AUTOSAR XML (schema 4-2-1)
package /RootP_STUB_BSWM_CORE1_AppASILB
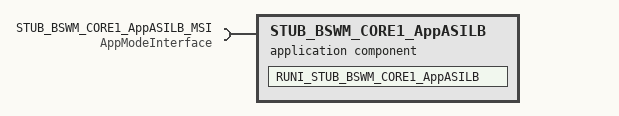
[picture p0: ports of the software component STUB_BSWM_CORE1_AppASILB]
  application sw component type STUB_BSWM_CORE1_AppASILB
    require port STUB_BSWM_CORE1_AppASILB_MSI: required-interface=AppModeInterface
    behavior IB_STUB_BSWM_CORE1_AppASILB: data-type-mapping=ApplicationModeMapping, handle-termination-and-restart=NO-SUPPORT
      swc mode switch event RUNI_STUB_BSWM_CORE1_AppASILB_ENTRY: start-on-event=RUNI_STUB_BSWM_CORE1_AppASILB, activation=ON-ENTRY, mode=STUB_BSWM_CORE1_AppASILB_MSI.AppMode.APP_SYNC_INIT2
      runnable RUNI_STUB_BSWM_CORE1_AppASILB
package /RootP_Implementatation
  swc implementation Implementatation_STUB_BSWM_CORE1_AppASILB: programming-language=C, sw-version=1.0.0, vendor-id=1, behavior=IB_STUB_BSWM_CORE1_AppASILB
    code-descriptors:
      code SRC: artifact-descriptors=autosar-engineering-object={short-label=EngObject, category=SWSRC}
    resource consumption Resources
      memory section CODE: sw-addrmethod=CODE_STUB_BSWM_CORE1_AppASILB
  sw addr method CODE_STUB_BSWM_CORE1_AppASILB: memory-allocation-keyword-policy=ADDR-METHOD-SHORT-NAME-AND-ALIGNMENT, section-type=CODE
